AUTOSAR XML (schema 4-0-3)
standard types defined: Boolean, UInt16, UInt8
package /AUTOSAR_Platform/DataConstrs
  range DC_Boolean: raw 0..1
  range DC_UInt16: raw 0..65535
  range DC_UInt8: raw 0..255
package /PATAC/MSM/ComponentTypes
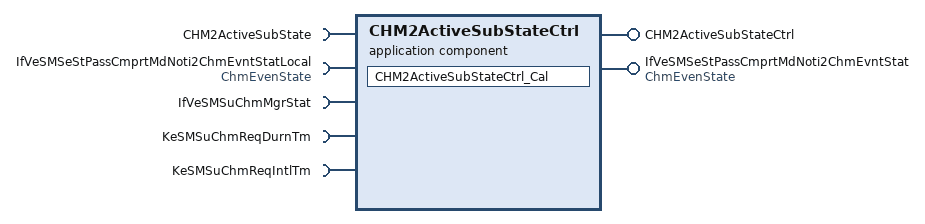
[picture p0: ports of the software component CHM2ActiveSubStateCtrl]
  application sw component type CHM2ActiveSubStateCtrl
    provide port CHM2ActiveSubStateCtrl: server-com-spec{operation=Cal, queue-length=1}, provided-interface=CHM2ActiveSubStateCtrl
    provide port IfVeSMSeStPassCmprtMdNoti2ChmEvntStat: nonqueued-sender-com-spec{data-element=ChmEvenState/Val, init-value=0}, provided-interface=ChmEvenState
    5 x require port:
      CHM2ActiveSubState: nonqueued-receiver-com-spec{data-element=CHM2ActiveSubState/Val, filter=data-filter-type=ALWAYS, init-value=0}, required-interface=CHM2ActiveSubState
      IfVeSMSeStPassCmprtMdNoti2ChmEvntStatLocal: nonqueued-receiver-com-spec{data-element=ChmEvenState/Val, filter=data-filter-type=ALWAYS, init-value=0}, required-interface=ChmEvenState
      IfVeSMSuChmMgrStat: nonqueued-receiver-com-spec{data-element=IfVeSMSuChmMgrStat/Val, filter=data-filter-type=ALWAYS, init-value=0}, required-interface=IfVeSMSuChmMgrStat
      KeSMSuChmReqDurnTm: parameter-require-com-spec{init-value=200, parameter=KeSMSuChmReqDurnTm/Val}, required-interface=KeSMSuChmReqDurnTm
      KeSMSuChmReqIntlTm: parameter-require-com-spec{init-value=50, parameter=KeSMSuChmReqIntlTm/Val}, required-interface=KeSMSuChmReqIntlTm
    behavior CHM2ActiveSubStateCtrl_InternalBehavior
      operation invoked event OIT_CHM2ActiveSubStateCtrl_Cal_CHM2ActiveSubStateCtrl_Cal: start-on-event=CHM2ActiveSubStateCtrl_Cal, operation=CHM2ActiveSubStateCtrl.Cal
      runnable CHM2ActiveSubStateCtrl_Cal
        data-receive-point-by-arguments:
          access REC_CHM2ActiveSubState_Val: accessed-variable=CHM2ActiveSubState.Val
          access REC_IfVeSMSeStPassCmprtMdNoti2ChmEvntStatLocal_Val: accessed-variable=IfVeSMSeStPassCmprtMdNoti2ChmEvntStatLocal.Val
          access REC_IfVeSMSuChmMgrStat_Val: accessed-variable=IfVeSMSuChmMgrStat.Val
        data-send-points:
          access SEND_IfVeSMSeStPassCmprtMdNoti2ChmEvntStat_Val: accessed-variable=IfVeSMSeStPassCmprtMdNoti2ChmEvntStat.Val
        parameter access PA_KeSMSuChmReqDurnTm_Val: accessed-parameter=KeSMSuChmReqDurnTm.Val
        parameter access PA_KeSMSuChmReqIntlTm_Val: accessed-parameter=KeSMSuChmReqIntlTm.Val
  swc implementation CHM2ActiveSubStateCtrl_Implementation: behavior=CHM2ActiveSubStateCtrl_InternalBehavior
    code-descriptors:
      code Default: artifact-descriptors=autosar-engineering-object={short-label=Default, category=SWSRC}
package /PATAC/MSM/ModeAdjust/DataType
  impl type EventSts1: category=VALUE, base-type=UInt8, sw-calibration-access=READ-ONLY, compu {0=EventSts_NoAct, 1=EventSts_Act, 2=EventSts_CancleChime}, type-emitter=RTE
package /PATAC/MSM/ModeAdjust/PortInterface
  client server interface CHM2ActiveSubStateCtrl
    operation Cal
  sender receiver interface CHM2ActiveSubState: invalidation-policy{data-element=CHM2ActiveSubState/Val, handle-invalid=DONT-INVALIDATE}
    data Val: type=Boolean
  sender receiver interface ChmEvenState: invalidation-policy{data-element=ChmEvenState/Val, handle-invalid=DONT-INVALIDATE}
    data Val: type=EventSts1
  sender receiver interface IfVeSMSuChmMgrStat: invalidation-policy{data-element=IfVeSMSuChmMgrStat/Val, handle-invalid=DONT-INVALIDATE}
    data Val: type=UInt16
package /PATAC/MSM/PortInterfaces
  parameter interface KeSMSuChmReqDurnTm
    parameter data prototype Val: sw-calibration-access=READ-WRITE, type=UInt8
  parameter interface KeSMSuChmReqIntlTm
    parameter data prototype Val: sw-calibration-access=READ-WRITE, type=UInt8
